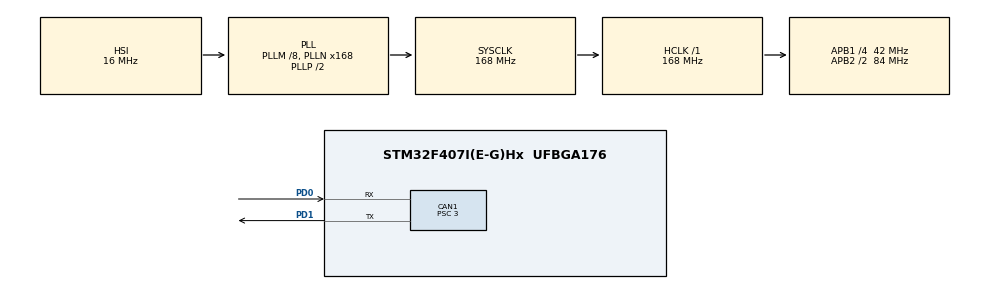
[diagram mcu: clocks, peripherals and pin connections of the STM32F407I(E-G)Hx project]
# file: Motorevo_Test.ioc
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CAN1.BS1=CAN_BS1_10TQ
CAN1.BS2=CAN_BS2_3TQ
CAN1.CalculateBaudRate=1000000
CAN1.CalculateTimeBit=1000
CAN1.CalculateTimeQuantum=71.42857142857143
CAN1.Prescaler=3
Mcu.Family=STM32F4
Mcu.Name=STM32F407I(E-G)Hx
Mcu.Package=UFBGA176
NVIC.CAN1_RX0_IRQn=true\:0\:0\:false\:false\:true\:true\:true\:true
NVIC.PriorityGroup=NVIC_PRIORITYGROUP_4
NVIC.TIM1_UP_TIM10_IRQn=true\:0\:0\:false\:false\:true\:true\:true\:true
PA13.Mode=Serial_Wire
PA13.Signal=SYS_JTMS-SWDIO
PA14.Mode=Serial_Wire
PA14.Signal=SYS_JTCK-SWCLK
PD0.Mode=CAN_Activate
PD0.Signal=CAN1_RX
PD1.Mode=CAN_Activate
PD1.Signal=CAN1_TX
PH0-OSC_IN.Mode=HSE-External-Oscillator
PH0-OSC_IN.Signal=RCC_OSC_IN
PH1-OSC_OUT.Mode=HSE-External-Oscillator
PH1-OSC_OUT.Signal=RCC_OSC_OUT
ProjectManager.HeapSize=0x200
ProjectManager.StackSize=0x400
ProjectManager.TargetToolchain=MDK-ARM V5.32
RCC.48MHZClocksFreq_Value=84000000
RCC.AHBFreq_Value=168000000
RCC.APB1CLKDivider=RCC_HCLK_DIV4
RCC.APB1Freq_Value=42000000
RCC.APB1TimFreq_Value=84000000
RCC.APB2CLKDivider=RCC_HCLK_DIV2
RCC.APB2Freq_Value=84000000
RCC.APB2TimFreq_Value=168000000
RCC.CortexFreq_Value=168000000
RCC.HCLKFreq_Value=168000000
RCC.HSE_VALUE=12000000
RCC.HSI_VALUE=16000000
RCC.LSE_VALUE=32768
RCC.PLLM=8
RCC.PLLN=168
RCC.SYSCLKFreq_VALUE=168000000
RCC.SYSCLKSource=RCC_SYSCLKSOURCE_PLLCLK
RCC.VCOOutputFreq_Value=336000000
TIM1.Period=1000-1
TIM1.Prescaler=168-1
VP_TIM1_VS_ClockSourceINT.Mode=Internal
board=custom

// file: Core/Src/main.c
/* USER CODE BEGIN Header */
/**
  ******************************************************************************
  * @file           : main.c
  * @brief          : Main program body
  ******************************************************************************
  * @attention
  *
  * Copyright (c) 2024 STMicroelectronics.
  * All rights reserved.
  *
  * This software is licensed under terms that can be found in the LICENSE file
  * in the root directory of this software component.
  * If no LICENSE file comes with this software, it is provided AS-IS.
  *
  ******************************************************************************
  */
/* USER CODE END Header */
#include "main.h"
#include "can.h"
#include "tim.h"
#include "gpio.h"

/* USER CODE BEGIN Includes */
#include "bsp_can.h"
#include "bsp_Motorevo.h"
/* USER CODE END Includes */

/* USER CODE BEGIN PTD */
int test_timWatch = 0;
/* USER CODE END PTD */

void SystemClock_Config(void);

/* USER CODE BEGIN 0 */
Motorevo_DataHandleTypeDef motor;
float target_position = 0;
float target_speed = 0.0f;
float target_torque = 0.0f;
float p_kp = 10.0f;
float p_kd = 1.0f;
float v_kp = 0.0f;
float v_ki = 0.0f;
float v_kd = 0.0f;

int key = 0;
void HAL_TIM_PeriodElapsedCallback(TIM_HandleTypeDef* htim)
{
	if(htim->Instance == TIM1)
	{
		test_timWatch++;
		if(test_timWatch > 5)
		{
			//Motorevo_motor_torque_control_mode(1, 50 );
			//Mototevo_motor_velocity_control_mode(1, target_speed, v_kp, v_ki, v_kd);
			Motorevo_motor_torque_position_mix_control_mode(0x01, target_position, target_speed, target_torque, p_kp, p_kd);

			if(key == 1)
			{
				Motorevo_set_zero_position(0x01);
				key = 0;
			}
			test_timWatch=0;
		}

	}
}

uint8_t test_rx_data[8];
void HAL_CAN_RxFifo0MsgPendingCallback(CAN_HandleTypeDef *hcan)
{
    CAN_RxHeaderTypeDef rx_header;

    HAL_CAN_GetRxMessage(hcan, CAN_RX_FIFO0, &rx_header, test_rx_data);

    switch (rx_header.StdId){
      case 0x01:{
        Motorevo_motor_canrx_communication(&motor, test_rx_data);
      }break;
    }

}

/* USER CODE END 0 */

int main(void)
{

  /* MCU Configuration--------------------------------------------------------*/

  /* Reset of all peripherals, Initializes the Flash interface and the Systick. */
  HAL_Init();

  /* Configure the system clock */
  SystemClock_Config();

  /* Initialize all configured peripherals */
  MX_GPIO_Init();
  MX_CAN1_Init();
  MX_TIM1_Init();
  /* USER CODE BEGIN 2 */
  can_filter_init();
  HAL_TIM_Base_Start_IT(&htim1);
  Motorevo_motor_init(&motor, 0x01, Motorevo_Motor_Status_TPMix);
  Motorevo_enter_motor_state(1);

  /* USER CODE END 2 */

  /* Infinite loop */
  while (1)
  {

  }
}

void SystemClock_Config(void)
{
  RCC_OscInitTypeDef RCC_OscInitStruct = {0};
  RCC_ClkInitTypeDef RCC_ClkInitStruct = {0};

  /** Configure the main internal regulator output voltage
  */
  __HAL_RCC_PWR_CLK_ENABLE();
  __HAL_PWR_VOLTAGESCALING_CONFIG(PWR_REGULATOR_VOLTAGE_SCALE1);

  /** Initializes the RCC Oscillators according to the specified parameters
  * in the RCC_OscInitTypeDef structure.
  */
  RCC_OscInitStruct.OscillatorType = RCC_OSCILLATORTYPE_HSI;
  RCC_OscInitStruct.HSIState = RCC_HSI_ON;
  RCC_OscInitStruct.HSICalibrationValue = RCC_HSICALIBRATION_DEFAULT;
  RCC_OscInitStruct.PLL.PLLState = RCC_PLL_ON;
  RCC_OscInitStruct.PLL.PLLSource = RCC_PLLSOURCE_HSI;
  RCC_OscInitStruct.PLL.PLLM = 8;
  RCC_OscInitStruct.PLL.PLLN = 168;
  RCC_OscInitStruct.PLL.PLLP = RCC_PLLP_DIV2;
  RCC_OscInitStruct.PLL.PLLQ = 4;
  if (HAL_RCC_OscConfig(&RCC_OscInitStruct) != HAL_OK)
  {
    Error_Handler();
  }

  /** Initializes the CPU, AHB and APB buses clocks
  */
  RCC_ClkInitStruct.ClockType = RCC_CLOCKTYPE_HCLK|RCC_CLOCKTYPE_SYSCLK
                              |RCC_CLOCKTYPE_PCLK1|RCC_CLOCKTYPE_PCLK2;
  RCC_ClkInitStruct.SYSCLKSource = RCC_SYSCLKSOURCE_PLLCLK;
  RCC_ClkInitStruct.AHBCLKDivider = RCC_SYSCLK_DIV1;
  RCC_ClkInitStruct.APB1CLKDivider = RCC_HCLK_DIV4;
  RCC_ClkInitStruct.APB2CLKDivider = RCC_HCLK_DIV2;

  if (HAL_RCC_ClockConfig(&RCC_ClkInitStruct, FLASH_LATENCY_5) != HAL_OK)
  {
    Error_Handler();
  }
}

void Error_Handler(void)
{
  __disable_irq();
  while (1)
  {
  }
}
